# apollo2 register map
Vendor: Ambiq Micro; Series: Apollo; File version: 1.0
CPU: CM4 r1p0, little endian, MPU, FPU, 3 interrupt priority bits
Registers are 32-bit, read-write, reset 0x0 unless marked. A register's access mark holds for its fields unless they carry their own. Offsets are from the block's base; [hi:lo] are bit positions.

## CACHECTRL — Flash Cache Controller
Base 0x40018000
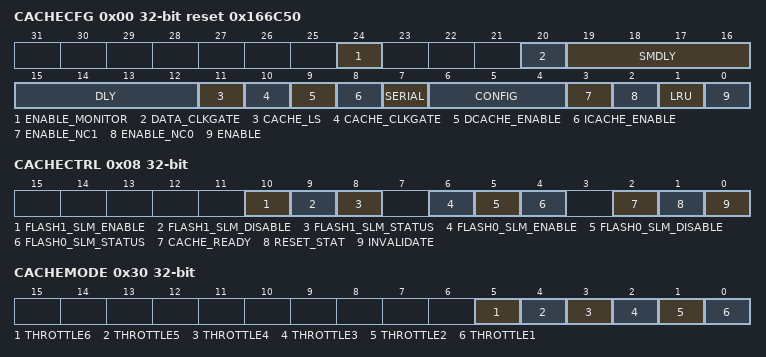
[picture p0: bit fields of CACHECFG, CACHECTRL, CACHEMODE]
0x00 CACHECFG reset 0x166C50 — Flash Cache Control Register
  [24] ENABLE_MONITOR — Enable Cache Monitoring Stats
  [20] DATA_CLKGATE — Enable clock gating of entire data array
  [19:16] SMDLY — Data RAM delay
  [15:12] DLY — Data RAM delay
  [11] CACHE_LS — Enable LS (light sleep) of cache RAMs. When this bit is set, the cache's RAMS will be put into light sleep mode while inactive. NOTE: if the cache is actively used, this may have an adverse affect on power since entering/exiting LS mode may consume more power than would be saved.
  [10] CACHE_CLKGATE — Enable clock gating of cache RAMs
  [9] DCACHE_ENABLE — Enable Flash Instruction Caching
  [8] ICACHE_ENABLE — Enable Flash Instruction Caching
  [7] SERIAL — Bitfield should always be programmed to 0.
  [6:4] CONFIG — Sets the cache configuration
    5=W2_128B_512E (Two-way set associative, 128-bit linesize, 512 entries (8 SRAMs active) value.)
  [3] ENABLE_NC1 — Enable Non-cacheable region 1
  [2] ENABLE_NC0 — Enable Non-cacheable region 0
  [1] LRU — Sets the cache replacement policy. 0=LRR (least recently replaced), 1=LRU (least recently used). LRR minimizes writes to the TAG SRAM.
  [0] ENABLE — Enables the flash cache controller. I/D caching enabled independently.
0x04 FLASHCFG reset 0x1 — Flash Control Register
  [2:0] RD_WAIT — Sets read waitstates (HCLK cycles)
0x08 CACHECTRL — Cache Control
  [10] FLASH1_SLM_ENABLE — Enable Flash Sleep Mode
  [9] FLASH1_SLM_DISABLE — Disable Flash Sleep Mode
  [8] FLASH1_SLM_STATUS — Flash Sleep Mode Status
  [6] FLASH0_SLM_ENABLE — Enable Flash Sleep Mode
  [5] FLASH0_SLM_DISABLE — Disable Flash Sleep Mode
  [4] FLASH0_SLM_STATUS — Flash Sleep Mode Status
  [2] CACHE_READY — Cache Ready Status (enabled and not processing an invalidate operation)
  [1] RESET_STAT — Writing a 1 to this bitfield will reset the cache monitor statistics (DMON0-3, IMON0-3). Statistic gathering can be paused/stopped by disabling the MONITOR_ENABLE bit in CACHECFG, which will maintain the count values until the stats are reset by writing this bitfield.
    1=CLEAR (Clear Cache Stats value.)
  [0] INVALIDATE — Writing a 1 to this bitfield invalidates the flash cache contents.
    1=GO (Initiate a programming operation to flash info. value.)
0x10 NCR0START — Flash Cache Noncachable Region 0 Start Address.
  [19:4] ADDR — Start address for non-cacheable region 0. The physical address of the start of this region should be programmed to this register and must be aligned to a 16-byte boundary (thus the lower 4 address bits are unused).
0x14 NCR0END — Flash Cache Noncachable Region 0 End
  [19:4] ADDR — End address for non-cacheable region 0. The physical address of the end of this region should be programmed to this register and must be aligned to a 16-byte boundary (thus the lower 4 address bits are unused).
0x18 NCR1START — Flash Cache Noncachable Region 1 Start
  [19:4] ADDR — Start address for non-cacheable region 1. The physical address of the start of this region should be programmed to this register and must be aligned to a 16-byte boundary (thus the lower 4 address bits are unused).
0x1C NCR1END — Flash Cache Noncachable Region 1 End
  [19:4] ADDR — End address for non-cacheable region 1. The physical address of the end of this region should be programmed to this register and must be aligned to a 16-byte boundary (thus the lower 4 address bits are unused).
0x30 CACHEMODE — Flash Cache Mode Register. Used to trim performance/power.
  [5] THROTTLE6 — Disallow Simultaneous Data RAM reads (from 2 line hits on each bus)
  [4] THROTTLE5 — Disallow Data RAM reads (from line hits) during lookup read ops
  [3] THROTTLE4 — Disallow Data RAM reads (from line hits) on tag RAM fill cycles
  [2] THROTTLE3 — Disallow cache data RAM writes on data RAM read cycles
  [1] THROTTLE2 — Disallow cache data RAM writes on tag RAM read cycles
  [0] THROTTLE1 — Disallow cache data RAM writes on tag RAM fill cycles
0x40 DMON0 — Data Cache Total Accesses
  [31:0] DACCESS_COUNT — Total accesses to data cache
0x44 DMON1 — Data Cache Tag Lookups
  [31:0] DLOOKUP_COUNT — Total tag lookups from data cache
0x48 DMON2 — Data Cache Hits
  [31:0] DHIT_COUNT — Cache hits from lookup operations
0x4C DMON3 — Data Cache Line Hits
  [31:0] DLINE_COUNT — Cache hits from line cache
0x50 IMON0 — Instruction Cache Total Accesses
  [31:0] IACCESS_COUNT — Total accesses to Instruction cache
0x54 IMON1 — Instruction Cache Tag Lookups
  [31:0] ILOOKUP_COUNT — Total tag lookups from Instruction cache
0x58 IMON2 — Instruction Cache Hits
  [31:0] IHIT_COUNT — Cache hits from lookup operations
0x5C IMON3 — Instruction Cache Line Hits
  [31:0] ILINE_COUNT — Cache hits from line cache

## Notices in the file
Copyright (C) 2012-2014 ARM Limited. All rights reserved.
Purpose: System Viewer Description (SVD) Example (Schema Version 1.1)
This is a description of a none-existent and incomplete device
for demonstration purposes only.
Redistribution and use in source and binary forms, with or without
modification, are permitted provided that the following conditions are met:
- Redistributions of source code must retain the above copyright
notice, this list of conditions and the following disclaimer.
- Redistributions in binary form must reproduce the above copyright
notice, this list of conditions and the following disclaimer in the
documentation and/or other materials provided with the distribution.
- Neither the name of ARM nor the names of its contributors may be used
to endorse or promote products derived from this software without
specific prior written permission.
THIS SOFTWARE IS PROVIDED BY THE COPYRIGHT HOLDERS AND CONTRIBUTORS "AS IS"
AND ANY EXPRESS OR IMPLIED WARRANTIES, INCLUDING, BUT NOT LIMITED TO, THE
IMPLIED WARRANTIES OF MERCHANTABILITY AND FITNESS FOR A PARTICULAR PURPOSE
ARE DISCLAIMED. IN NO EVENT SHALL COPYRIGHT HOLDERS AND CONTRIBUTORS BE
LIABLE FOR ANY DIRECT, INDIRECT, INCIDENTAL, SPECIAL, EXEMPLARY, OR
CONSEQUENTIAL DAMAGES (INCLUDING, BUT NOT LIMITED TO, PROCUREMENT OF
SUBSTITUTE GOODS OR SERVICES; LOSS OF USE, DATA, OR PROFITS; OR BUSINESS
INTERRUPTION) HOWEVER CAUSED AND ON ANY THEORY OF LIABILITY, WHETHER IN
CONTRACT, STRICT LIABILITY, OR TORT (INCLUDING NEGLIGENCE OR OTHERWISE)
ARISING IN ANY WAY OUT OF THE USE OF THIS SOFTWARE, EVEN IF ADVISED OF THE
POSSIBILITY OF SUCH DAMAGE.
